# STM32H7x5 register map
File version: 1.1
CPU: CM7 r0p0, little endian, no MPU, no FPU, 3 interrupt priority bits
Registers are 32-bit, read-write, reset 0x0 unless marked. A register's access mark holds for its fields unless they carry their own. Offsets are from the block's base; [hi:lo] are bit positions.

## Ethernet_MAC — Ethernet: media access control (MAC)
Base 0x40028000
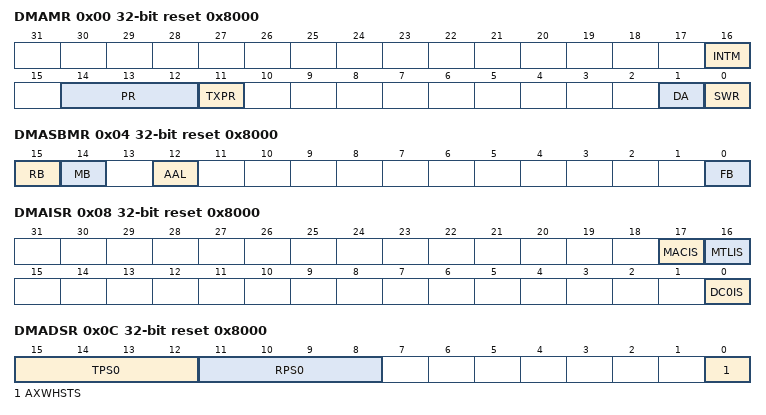
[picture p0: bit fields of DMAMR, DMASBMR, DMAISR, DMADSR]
0x00 DMAMR reset 0x8000 — DMA mode register
  [16] INTM — Interrupt Mode
  [14:12] PR — Priority ratio
  [11] TXPR — Transmit priority
  [1] DA — DMA Tx or Rx Arbitration Scheme
  [0] SWR — Software Reset
0x04 DMASBMR reset 0x8000 — System bus mode register
  [15] RB — Rebuild INCRx Burst
  [14] MB — Mixed Burst
  [12] AAL — Address-Aligned Beats
  [0] FB — Fixed Burst Length
0x08 DMAISR reset 0x8000 — Interrupt status register
  [17] MACIS — MAC Interrupt Status
  [16] MTLIS — MTL Interrupt Status
  [0] DC0IS — DMA Channel Interrupt Status
0x0C DMADSR reset 0x8000 — Debug status register
  [15:12] TPS0 — DMA Channel Transmit Process State
  [11:8] RPS0 — DMA Channel Receive Process State
  [0] AXWHSTS — AHB Master Write Channel
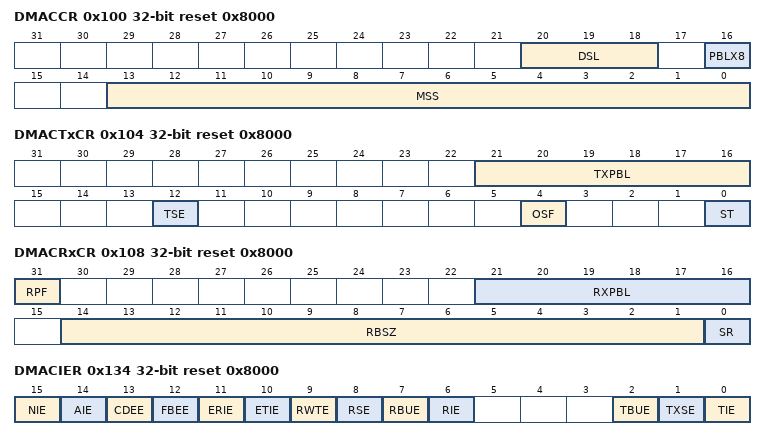
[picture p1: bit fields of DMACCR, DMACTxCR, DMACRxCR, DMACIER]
0x100 DMACCR reset 0x8000 — Channel control register
  [20:18] DSL — Descriptor Skip Length
  [16] PBLX8 — 8xPBL mode
  [13:0] MSS — Maximum Segment Size
0x104 DMACTxCR reset 0x8000 — Channel transmit control register
  [21:16] TXPBL — Transmit Programmable Burst Length
  [12] TSE — TCP Segmentation Enabled
  [4] OSF — Operate on Second Packet
  [0] ST — Start or Stop Transmission Command
0x108 DMACRxCR reset 0x8000 — Channel receive control register
  [31] RPF — DMA Rx Channel Packet Flush
  [21:16] RXPBL
  [14:1] RBSZ — Receive Buffer size
  [0] SR — Start or Stop Receive Command
0x114 DMACTxDLAR reset 0x8000 — Channel Tx descriptor list address register
  [31:2] TDESLA — Start of Transmit List
0x11C DMACRxDLAR reset 0x8000 — Channel Rx descriptor list address register
  [31:2] RDESLA — Start of Receive List
0x120 DMACTxDTPR reset 0x8000 — Channel Tx descriptor tail pointer register
  [31:2] TDT — Transmit Descriptor Tail Pointer
0x128 DMACRxDTPR reset 0x8000 — Channel Rx descriptor tail pointer register
  [31:2] RDT — Receive Descriptor Tail Pointer
0x12C DMACTxRLR reset 0x8000 — Channel Tx descriptor ring length register
  [9:0] TDRL — Transmit Descriptor Ring Length
0x130 DMACRxRLR reset 0x8000 — Channel Rx descriptor ring length register
  [9:0] RDRL — Receive Descriptor Ring Length
0x134 DMACIER reset 0x8000 — Channel interrupt enable register
  [15] NIE — Normal Interrupt Summary Enable
  [14] AIE — Abnormal Interrupt Summary Enable
  [13] CDEE — Context Descriptor Error Enable
  [12] FBEE — Fatal Bus Error Enable
  [11] ERIE — Early Receive Interrupt Enable
  [10] ETIE — Early Transmit Interrupt Enable
  [9] RWTE — Receive Watchdog Timeout Enable
  [8] RSE — Receive Stopped Enable
  [7] RBUE — Receive Buffer Unavailable Enable
  [6] RIE — Receive Interrupt Enable
  [2] TBUE — Transmit Buffer Unavailable Enable
  [1] TXSE — Transmit Stopped Enable
  [0] TIE — Transmit Interrupt Enable
0x138 DMACRxIWTR reset 0x8000 — Channel Rx interrupt watchdog timer register
  [7:0] RWT — Receive Interrupt Watchdog Timer Count
0x144 DMACCATxDR reset 0x8000 — Channel current application transmit descriptor register
  [31:0] CURTDESAPTR — Application Transmit Descriptor Address Pointer
0x14C DMACCARxDR reset 0x8000 — Channel current application receive descriptor register
  [31:0] CURRDESAPTR — Application Receive Descriptor Address Pointer
0x154 DMACCATxBR reset 0x8000 — Channel current application transmit buffer register
  [31:0] CURTBUFAPTR — Application Transmit Buffer Address Pointer
0x15C DMACCARxBR reset 0x8000 — Channel current application receive buffer register
  [31:0] CURRBUFAPTR — Application Receive Buffer Address Pointer
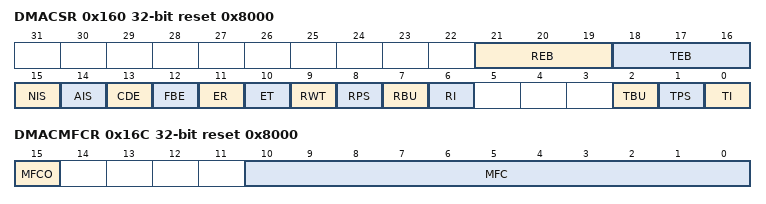
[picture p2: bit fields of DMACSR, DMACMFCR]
0x160 DMACSR reset 0x8000 — Channel status register
  [21:19] REB — Rx DMA Error Bits
  [18:16] TEB — Tx DMA Error Bits
  [15] NIS — Normal Interrupt Summary
  [14] AIS — Abnormal Interrupt Summary
  [13] CDE — Context Descriptor Error
  [12] FBE — Fatal Bus Error
  [11] ER — Early Receive Interrupt
  [10] ET — Early Transmit Interrupt
  [9] RWT — Receive Watchdog Timeout
  [8] RPS — Receive Process Stopped
  [7] RBU — Receive Buffer Unavailable
  [6] RI — Receive Interrupt
  [2] TBU — Transmit Buffer Unavailable
  [1] TPS — Transmit Process Stopped
  [0] TI — Transmit Interrupt
0x16C DMACMFCR ro reset 0x8000 — Channel missed frame count register
  [15] MFCO — Overflow status of the MFC Counter
  [10:0] MFC — Dropped Packet Counters
